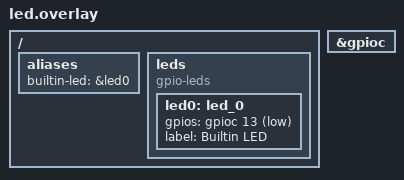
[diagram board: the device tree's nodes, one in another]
/* SPDX-License-Identifier: Apache-2.0 */

/ {
	aliases {
		builtin-led = &led0;
	};

	leds {
		compatible = "gpio-leds";

		led0: led_0 {
			gpios = <&gpioc 13 GPIO_ACTIVE_LOW>;
			label = "Builtin LED";
		};
	};
};


&gpioc {
	status = "okay";
};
